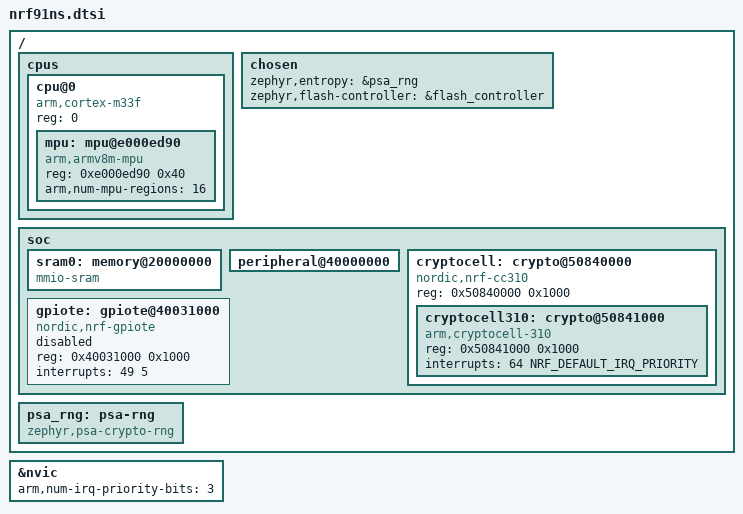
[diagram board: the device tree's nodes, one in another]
/*
 * Copyright (c) 2018 Nordic Semiconductor ASA
 *
 * SPDX-License-Identifier: Apache-2.0
 */

#include <arm/armv8-m.dtsi>
#include "nrf_common.dtsi"

/ {
	cpus {
		#address-cells = <1>;
		#size-cells = <0>;

		cpu@0 {
			device_type = "cpu";
			compatible = "arm,cortex-m33f";
			reg = <0>;
			#address-cells = <1>;
			#size-cells = <1>;

			mpu: mpu@e000ed90 {
				compatible = "arm,armv8m-mpu";
				reg = <0xe000ed90 0x40>;
				arm,num-mpu-regions = <16>;
			};
		};
	};

	chosen {
		zephyr,entropy = &psa_rng;
		zephyr,flash-controller = &flash_controller;
	};

	soc {
		sram0: memory@20000000 {
			compatible = "mmio-sram";
		};

		peripheral@40000000 {
			#address-cells = <1>;
			#size-cells = <1>;
			ranges = <0x0 0x40000000 0x10000000>;

			/* Common nRF91 peripherals description. */
			#include "nrf91_peripherals.dtsi"
		};

		/* Cryptocell is a secure-only peripheral, but the availability
		 * of this peripheral and the cryptocell variant is still useful
		 * information for the non-secure application as it can access
		 * crypto features through secure-services.
		 */
		cryptocell: crypto@50840000 {
			compatible = "nordic,nrf-cc310";
			reg = <0x50840000 0x1000>;
			status = "okay";
			#address-cells = <1>;
			#size-cells = <1>;
			cryptocell310: crypto@50841000 {
				compatible = "arm,cryptocell-310";
				reg = <0x50841000 0x1000>;
				interrupts = <64 NRF_DEFAULT_IRQ_PRIORITY>;
			};
		};

		/* Additional Non-Secure peripherals */
		gpiote: gpiote@40031000 {
			compatible = "nordic,nrf-gpiote";
			reg = <0x40031000 0x1000>;
			interrupts = <49 5>;
			status = "disabled";
		};
	};

	psa_rng: psa-rng {
		compatible = "zephyr,psa-crypto-rng";
		status = "okay";
	};
};

&nvic {
	arm,num-irq-priority-bits = <3>;
};
